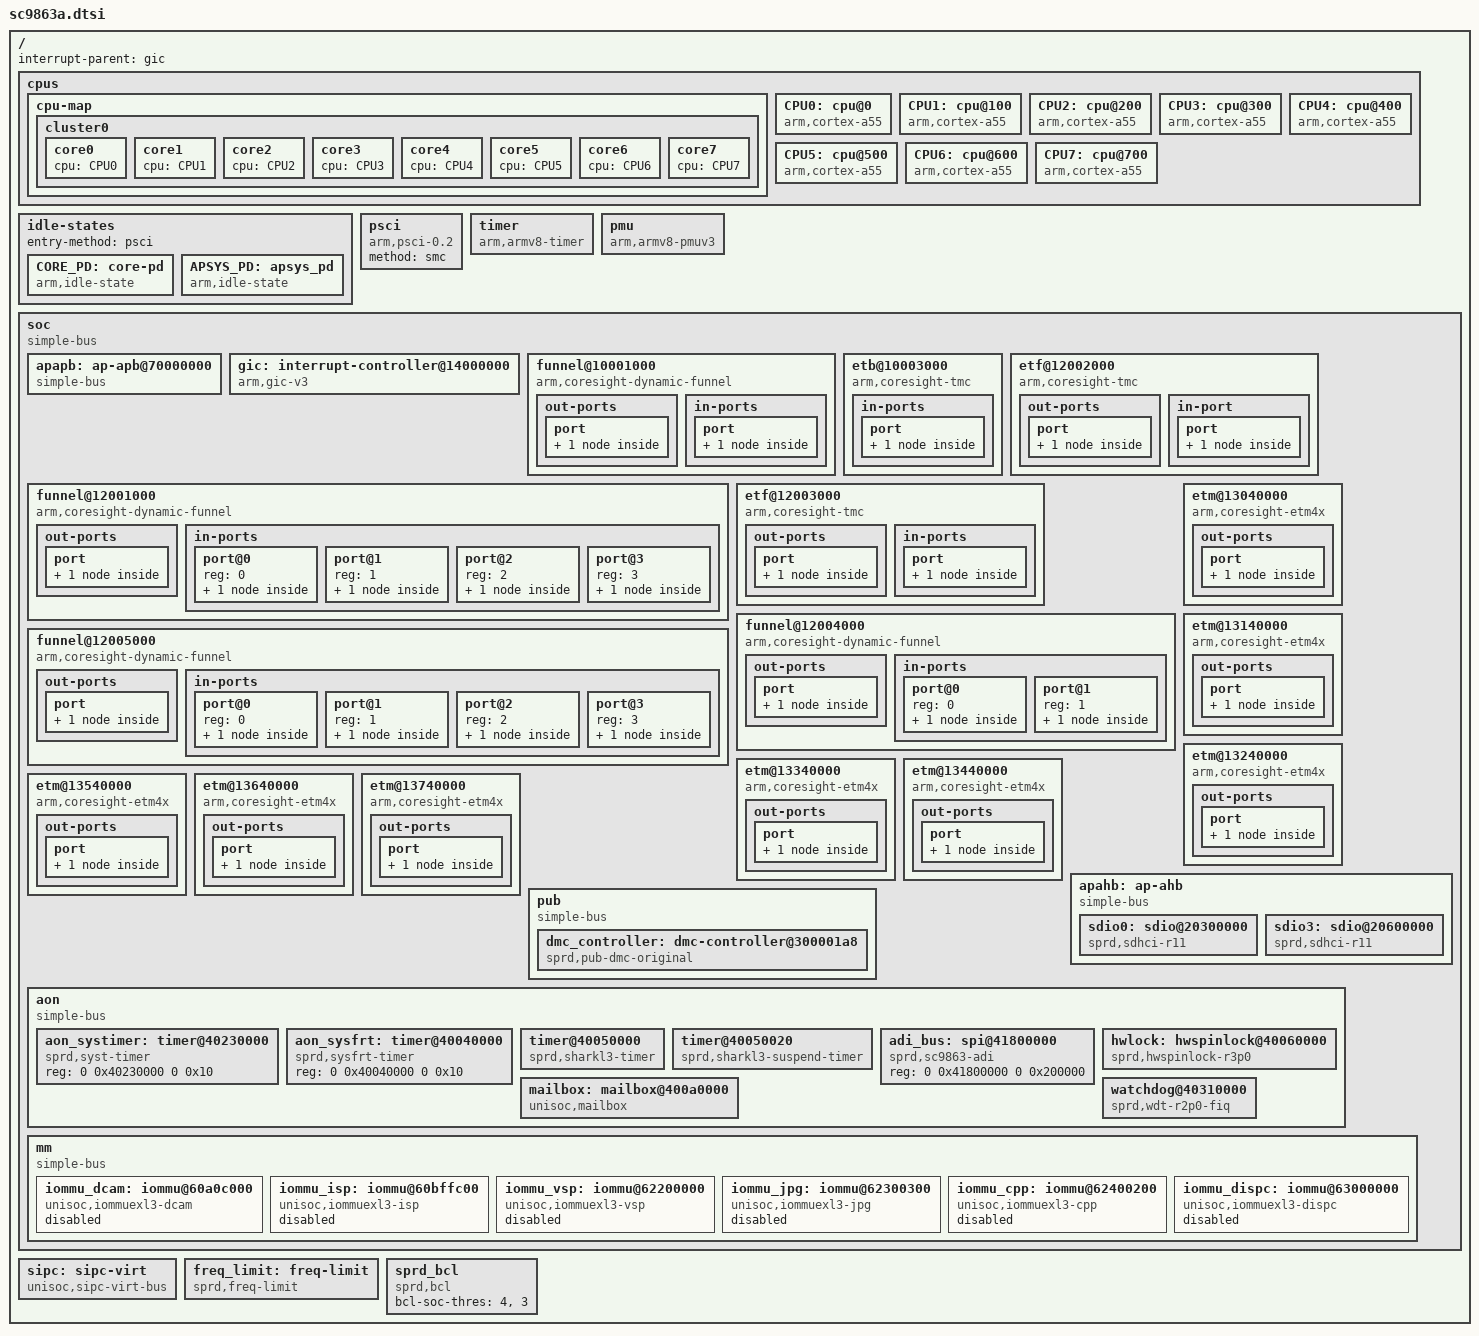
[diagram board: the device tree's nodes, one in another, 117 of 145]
// SPDX-License-Identifier: GPL-2.0-only
/*
 * Unisoc SC9863A SoC DTS file
 *
 * Copyright (C) 2019, Unisoc Inc.
 */

#include <dt-bindings/clock/sprd,sc9863a-clk.h>
#include <dt-bindings/reset/sprd,sc9863a-reset.h>
#include <dt-bindings/interrupt-controller/arm-gic.h>

/ {

	interrupt-parent = <&gic>;
	#address-cells = <2>;
	#size-cells = <2>;

	cpus {
		#address-cells = <2>;
		#size-cells = <0>;

		cpu-map {
			cluster0 {
				core0 {
					cpu = <&CPU0>;
				};
				core1 {
					cpu = <&CPU1>;
				};
				core2 {
					cpu = <&CPU2>;
				};
				core3 {
					cpu = <&CPU3>;
				};
				core4 {
					cpu = <&CPU4>;
				};
				core5 {
					cpu = <&CPU5>;
				};
				core6 {
					cpu = <&CPU6>;
				};
				core7 {
					cpu = <&CPU7>;
				};
			};
		};

		CPU0: cpu@0 {
			device_type = "cpu";
			compatible = "arm,cortex-a55";
			reg = <0x0 0x0>;
			enable-method = "psci";
			cpu-idle-states = <&CORE_PD &APSYS_PD>;
			capacity-dmips-mhz = <1024>;
			dynamic-power-coefficient = <100>;
			sugov_slack_timer;
			#cooling-cells = <2>;
		};

		CPU1: cpu@100 {
			device_type = "cpu";
			compatible = "arm,cortex-a55";
			reg = <0x0 0x100>;
			enable-method = "psci";
			cpu-idle-states = <&CORE_PD &APSYS_PD>;
			capacity-dmips-mhz = <1024>;
			dynamic-power-coefficient = <100>;
			#cooling-cells = <2>;
		};

		CPU2: cpu@200 {
			device_type = "cpu";
			compatible = "arm,cortex-a55";
			reg = <0x0 0x200>;
			enable-method = "psci";
			cpu-idle-states = <&CORE_PD &APSYS_PD>;
			capacity-dmips-mhz = <1024>;
			dynamic-power-coefficient = <100>;
			#cooling-cells = <2>;
		};

		CPU3: cpu@300 {
			device_type = "cpu";
			compatible = "arm,cortex-a55";
			reg = <0x0 0x300>;
			enable-method = "psci";
			cpu-idle-states = <&CORE_PD &APSYS_PD>;
			capacity-dmips-mhz = <1024>;
			dynamic-power-coefficient = <100>;
			#cooling-cells = <2>;
		};

		CPU4: cpu@400 {
			device_type = "cpu";
			compatible = "arm,cortex-a55";
			reg = <0x0 0x400>;
			enable-method = "psci";
			cpu-idle-states = <&CORE_PD &APSYS_PD>;
			capacity-dmips-mhz = <1024>;
			dynamic-power-coefficient = <153>;
			#cooling-cells = <2>;
		};

		CPU5: cpu@500 {
			device_type = "cpu";
			compatible = "arm,cortex-a55";
			reg = <0x0 0x500>;
			enable-method = "psci";
			cpu-idle-states = <&CORE_PD &APSYS_PD>;
			capacity-dmips-mhz = <1024>;
			dynamic-power-coefficient = <153>;
			#cooling-cells = <2>;
		};

		CPU6: cpu@600 {
			device_type = "cpu";
			compatible = "arm,cortex-a55";
			reg = <0x0 0x600>;
			enable-method = "psci";
			cpu-idle-states = <&CORE_PD &APSYS_PD>;
			capacity-dmips-mhz = <1024>;
			dynamic-power-coefficient = <153>;
			#cooling-cells = <2>;
		};

		CPU7: cpu@700 {
			device_type = "cpu";
			compatible = "arm,cortex-a55";
			reg = <0x0 0x700>;
			enable-method = "psci";
			cpu-idle-states = <&CORE_PD &APSYS_PD>;
			capacity-dmips-mhz = <1024>;
			dynamic-power-coefficient = <153>;
			#cooling-cells = <2>;
		};
	};

	idle-states {
		entry-method = "psci";
		CORE_PD: core-pd {
			compatible = "arm,idle-state";
			entry-latency-us = <4000>;
			exit-latency-us = <4000>;
			min-residency-us = <10000>;
			local-timer-stop;
			arm,psci-suspend-param = <0x00010000>;
		};
		APSYS_PD: apsys_pd {
			compatible = "arm,idle-state";
			entry-latency-us = <12000>;
			exit-latency-us = <12000>;
			min-residency-us = <15000>;
			local-timer-stop;
			arm,psci-suspend-param = <0x02010000>;
		};
	};

	psci {
		compatible = "arm,psci-0.2";
		method = "smc";
	};

	timer {
		compatible = "arm,armv8-timer";
		interrupts = <GIC_PPI 13 IRQ_TYPE_LEVEL_HIGH>, /* Physical Secure PPI */
			     <GIC_PPI 14 IRQ_TYPE_LEVEL_HIGH>, /* Physical Non-Secure PPI */
			     <GIC_PPI 11 IRQ_TYPE_LEVEL_HIGH>, /* Virtual PPI */
			     <GIC_PPI 10 IRQ_TYPE_LEVEL_HIGH>; /* Hipervisor PPI */
		arm,no-tick-in-suspend;
	};

	pmu {
		compatible = "arm,armv8-pmuv3";
		interrupts = <GIC_SPI 144 IRQ_TYPE_LEVEL_HIGH>,
			     <GIC_SPI 145 IRQ_TYPE_LEVEL_HIGH>,
			     <GIC_SPI 146 IRQ_TYPE_LEVEL_HIGH>,
			     <GIC_SPI 147 IRQ_TYPE_LEVEL_HIGH>,
			     <GIC_SPI 148 IRQ_TYPE_LEVEL_HIGH>,
			     <GIC_SPI 149 IRQ_TYPE_LEVEL_HIGH>,
			     <GIC_SPI 150 IRQ_TYPE_LEVEL_HIGH>,
			     <GIC_SPI 151 IRQ_TYPE_LEVEL_HIGH>;
	};

	soc: soc {

		compatible = "simple-bus";
		#address-cells = <2>;
		#size-cells = <2>;
		ranges;

		apapb: ap-apb@70000000 {
			compatible = "simple-bus";
			#address-cells = <1>;
			#size-cells = <1>;
			ranges = <0 0x0 0x70000000 0x10000000>;
		};

		gic: interrupt-controller@14000000 {
			compatible = "arm,gic-v3";
			#interrupt-cells = <3>;
			#address-cells = <2>;
			#size-cells = <2>;
			ranges;
			redistributor-stride = <0x0 0x20000>;	/* 128KB stride */
			#redistributor-regions = <1>;
			interrupt-controller;
			reg = <0x0 0x14000000 0 0x20000>,	/* GICD */
			      <0x0 0x14040000 0 0x100000>;	/* GICR */
			interrupts = <GIC_PPI 9 IRQ_TYPE_LEVEL_HIGH>;
		};

		funnel@10001000 {
			compatible = "arm,coresight-dynamic-funnel", "arm,primecell";
			reg = <0 0x10001000 0 0x1000>;
			clocks = <&ext_26m>;
			clock-names = "apb_pclk";

			out-ports {
				port {
					funnel_soc_out_port: endpoint {
						remote-endpoint = <&etb_in>;
					};
				};
			};

			in-ports {
				port {
					funnel_soc_in_port: endpoint {
						remote-endpoint =
						<&funnel_ca55_out_port>;
					};
				};
			};
		};

		etb@10003000 {
			compatible = "arm,coresight-tmc", "arm,primecell";
			reg = <0 0x10003000 0 0x1000>;
			clocks = <&ext_26m>;
			clock-names = "apb_pclk";

			in-ports {
				port {
					etb_in: endpoint {
						remote-endpoint =
						<&funnel_soc_out_port>;
					};
				};
			};
		};

		funnel@12001000 {
			compatible = "arm,coresight-dynamic-funnel", "arm,primecell";
			reg = <0 0x12001000 0 0x1000>;
			clocks = <&ext_26m>;
			clock-names = "apb_pclk";

			out-ports {
				port {
					funnel_little_out_port: endpoint {
						remote-endpoint =
						<&etf_little_in>;
					};
				};
			};

			in-ports {
				#address-cells = <1>;
				#size-cells = <0>;

				port@0 {
					reg = <0>;
					funnel_little_in_port0: endpoint {
						remote-endpoint = <&etm0_out>;
					};
				};

				port@1 {
					reg = <1>;
					funnel_little_in_port1: endpoint {
						remote-endpoint = <&etm1_out>;
					};
				};

				port@2 {
					reg = <2>;
					funnel_little_in_port2: endpoint {
						remote-endpoint = <&etm2_out>;
					};
				};

				port@3 {
					reg = <3>;
					funnel_little_in_port3: endpoint {
						remote-endpoint = <&etm3_out>;
					};
				};
			};
		};

		etf@12002000 {
			compatible = "arm,coresight-tmc", "arm,primecell";
			reg = <0 0x12002000 0 0x1000>;
			clocks = <&ext_26m>;
			clock-names = "apb_pclk";

			out-ports {
				port {
					etf_little_out: endpoint {
						remote-endpoint =
						<&funnel_ca55_in_port0>;
					};
				};
			};

			in-port {
				port {
					etf_little_in: endpoint {
						remote-endpoint =
						<&funnel_little_out_port>;
					};
				};
			};
		};

		etf@12003000 {
			compatible = "arm,coresight-tmc", "arm,primecell";
			reg = <0 0x12003000 0 0x1000>;
			clocks = <&ext_26m>;
			clock-names = "apb_pclk";

			out-ports {
				port {
					etf_big_out: endpoint {
						remote-endpoint =
						<&funnel_ca55_in_port1>;
					};
				};
			};

			in-ports {
				port {
					etf_big_in: endpoint {
						remote-endpoint =
						<&funnel_big_out_port>;
					};
				};
			};
		};

		funnel@12004000 {
			compatible = "arm,coresight-dynamic-funnel", "arm,primecell";
			reg = <0 0x12004000 0 0x1000>;
			clocks = <&ext_26m>;
			clock-names = "apb_pclk";

			out-ports {
				port {
					funnel_ca55_out_port: endpoint {
						remote-endpoint =
						<&funnel_soc_in_port>;
					};
				};
			};

			in-ports {
				#address-cells = <1>;
				#size-cells = <0>;

				port@0 {
					reg = <0>;
					funnel_ca55_in_port0: endpoint {
						remote-endpoint =
						<&etf_little_out>;
					};
				};

				port@1 {
					reg = <1>;
					funnel_ca55_in_port1: endpoint {
						remote-endpoint =
						<&etf_big_out>;
					};
				};
			};
		};

		funnel@12005000 {
			compatible = "arm,coresight-dynamic-funnel", "arm,primecell";
			reg = <0 0x12005000 0 0x1000>;
			clocks = <&ext_26m>;
			clock-names = "apb_pclk";

			out-ports {
				port {
					funnel_big_out_port: endpoint {
						remote-endpoint =
						<&etf_big_in>;
					};
				};
			};

			in-ports {
				#address-cells = <1>;
				#size-cells = <0>;

				port@0 {
					reg = <0>;
					funnel_big_in_port0: endpoint {
						remote-endpoint = <&etm4_out>;
					};
				};

				port@1 {
					reg = <1>;
					funnel_big_in_port1: endpoint {
						remote-endpoint = <&etm5_out>;
					};
				};

				port@2 {
					reg = <2>;
					funnel_big_in_port2: endpoint {
						remote-endpoint = <&etm6_out>;
					};
				};

				port@3 {
					reg = <3>;
					funnel_big_in_port3: endpoint {
						remote-endpoint = <&etm7_out>;
					};
				};
			};
		};

		etm@13040000 {
			compatible = "arm,coresight-etm4x", "arm,primecell";
			reg = <0 0x13040000 0 0x1000>;
			cpu = <&CPU0>;
			clocks = <&ext_26m>;
			clock-names = "apb_pclk";

			out-ports {
				port {
					etm0_out: endpoint {
						remote-endpoint =
						<&funnel_little_in_port0>;
					};
				};
			};
		};

		etm@13140000 {
			compatible = "arm,coresight-etm4x", "arm,primecell";
			reg = <0 0x13140000 0 0x1000>;
			cpu = <&CPU1>;
			clocks = <&ext_26m>;
			clock-names = "apb_pclk";

			out-ports {
				port {
					etm1_out: endpoint {
						remote-endpoint =
						<&funnel_little_in_port1>;
					};
				};
			};
		};

		etm@13240000 {
			compatible = "arm,coresight-etm4x", "arm,primecell";
			reg = <0 0x13240000 0 0x1000>;
			cpu = <&CPU2>;
			clocks = <&ext_26m>;
			clock-names = "apb_pclk";

			out-ports {
				port {
					etm2_out: endpoint {
						remote-endpoint =
						<&funnel_little_in_port2>;
					};
				};
			};
		};

		etm@13340000 {
			compatible = "arm,coresight-etm4x", "arm,primecell";
			reg = <0 0x13340000 0 0x1000>;
			cpu = <&CPU3>;
			clocks = <&ext_26m>;
			clock-names = "apb_pclk";

			out-ports {
				port {
					etm3_out: endpoint {
						remote-endpoint =
						<&funnel_little_in_port3>;
					};
				};
			};
		};

		etm@13440000 {
			compatible = "arm,coresight-etm4x", "arm,primecell";
			reg = <0 0x13440000 0 0x1000>;
			cpu = <&CPU4>;
			clocks = <&ext_26m>;
			clock-names = "apb_pclk";

			out-ports {
				port {
					etm4_out: endpoint {
						remote-endpoint =
						<&funnel_big_in_port0>;
					};
				};
			};
		};

		etm@13540000 {
			compatible = "arm,coresight-etm4x", "arm,primecell";
			reg = <0 0x13540000 0 0x1000>;
			cpu = <&CPU5>;
			clocks = <&ext_26m>;
			clock-names = "apb_pclk";

			out-ports {
				port {
					etm5_out: endpoint {
						remote-endpoint =
						<&funnel_big_in_port1>;
					};
				};
			};
		};

		etm@13640000 {
			compatible = "arm,coresight-etm4x", "arm,primecell";
			reg = <0 0x13640000 0 0x1000>;
			cpu = <&CPU6>;
			clocks = <&ext_26m>;
			clock-names = "apb_pclk";

			out-ports {
				port {
					etm6_out: endpoint {
						remote-endpoint =
						<&funnel_big_in_port2>;
					};
				};
			};
		};

		etm@13740000 {
			compatible = "arm,coresight-etm4x", "arm,primecell";
			reg = <0 0x13740000 0 0x1000>;
			cpu = <&CPU7>;
			clocks = <&ext_26m>;
			clock-names = "apb_pclk";

			out-ports {
				port {
					etm7_out: endpoint {
						remote-endpoint =
						<&funnel_big_in_port3>;
					};
				};
			};
		};

		apahb: ap-ahb {
			compatible = "simple-bus";
			#address-cells = <2>;
			#size-cells = <2>;
			ranges;

			sdio0: sdio@20300000 {
				compatible  = "sprd,sdhci-r11";
				reg = <0 0x20300000 0 0x1000>;
				interrupts = <GIC_SPI 57 IRQ_TYPE_LEVEL_HIGH>;

				clock-names = "sdio", "enable";
				clocks = <&aon_clk CLK_SDIO0_2X>,
					 <&apahb_gate CLK_SDIO0_EB>;
				assigned-clocks = <&aon_clk CLK_SDIO0_2X>;
				assigned-clock-parents = <&rpll CLK_RPLL_390M>;
			};

			sdio3: sdio@20600000 {
				compatible  = "sprd,sdhci-r11";
				reg = <0 0x20600000 0 0x1000>;
				interrupts = <GIC_SPI 60 IRQ_TYPE_LEVEL_HIGH>;

				clock-names = "sdio", "enable";
				clocks = <&aon_clk CLK_EMMC_2X>,
					 <&apahb_gate CLK_EMMC_EB>;
				assigned-clocks = <&aon_clk CLK_EMMC_2X>;
				assigned-clock-parents = <&rpll CLK_RPLL_390M>;
			};
		};

		pub: pub {
			compatible = "simple-bus";
			#address-cells = <2>;
			#size-cells = <2>;
			ranges;

			dmc_controller: dmc-controller@300001a8 {
				compatible = "sprd,pub-dmc-original";
				reg = <0x0 0x300001a8 0x0 0x100>,
					<0x0 0x30000000 0x0 0x12c>;
			};
		};

		aon: aon {
			compatible = "simple-bus";
			#address-cells = <2>;
			#size-cells = <2>;
			ranges;

			aon_systimer: timer@40230000 {
				compatible = "sprd,syst-timer";
				reg = <0 0x40230000 0 0x10>;
			};

			aon_sysfrt: timer@40040000 {
				compatible = "sprd,sysfrt-timer";
				reg = <0 0x40040000 0 0x10>;
			};

			timer@40050000 {
				compatible = "sprd,sharkl3-timer",
						"sprd,sc9860-timer";
				reg = <0 0x40050000 0 0x14>;
				interrupts = <GIC_SPI 27 IRQ_TYPE_LEVEL_HIGH>;
				clocks = <&ext_32k>;
			};

			timer@40050020 {
				compatible = "sprd,sharkl3-suspend-timer",
					"sprd,sc9860-suspend-timer";
				reg = <0 0x40050020 0 0x14>;
				clocks = <&ext_32k>;
			};

			adi_bus: spi@41800000 {
				compatible = "sprd,sc9863-adi";
				reg = <0 0x41800000 0 0x200000>;
				#address-cells = <1>;
				#size-cells = <0>;
			};

			hwlock: hwspinlock@40060000 {
				compatible = "sprd,hwspinlock-r3p0";
				reg = <0 0x40060000 0 0x10000>;
				#hwlock-cells = <1>;
				clock-names = "enable";
				clocks = <&aonapb_gate CLK_SPLK_EB>;
			};

			mailbox: mailbox@400a0000 {
				compatible = "unisoc,mailbox";
				reg = <0 0x400a0000 0 0x8000>,
				      <0 0x400a8000 0 0x8000>;
				reg-names = "inbox", "outbox";
				sprd,mailbox_clk = <&aon_apb_regs 0x4 0x200000>;
				interrupts = <GIC_SPI 68 IRQ_TYPE_LEVEL_HIGH>,
					     <GIC_SPI 69 IRQ_TYPE_LEVEL_HIGH>,
					     <GIC_SPI 119 IRQ_TYPE_LEVEL_HIGH>;
				interrupt-names = "inbox", "outbox", "oob-outbox";
				#mbox-cells = <2>;
			};
			watchdog@40310000 {
				compatible = "sprd,wdt-r2p0-fiq";
				reg = <0 0x40310000 0 0x1000>;
				interrupts = <GIC_SPI 124 IRQ_TYPE_LEVEL_HIGH>;
				timeout-sec = <30>;
				clock-names = "enable", "rtc_enable";
				clocks = <&aonapb_gate CLK_CA53_WDG_EB>,
					<&aonapb_gate CLK_CA53_WDG_RTC_EB>;
			};
		};

		mm: mm {
			compatible = "simple-bus";
			#address-cells = <2>;
			#size-cells = <2>;
			ranges;

			iommu_dcam: iommu@60a0c000 {
				compatible = "unisoc,iommuexl3-dcam";
				reg = <0 0x60a00000 0 0xc000>,
					<0 0x60a0c000 0 0x60>;
				iova-base = <0x40000000>;
				iova-size = <0x20000000>;
				reg_name = "mmu_interrupt_reg", "mmu_reg";
				status = "disabled";
				#iommu-cells = <0>;
			};
			iommu_isp: iommu@60bffc00 {
				compatible = "unisoc,iommuexl3-isp";
				/* sharkl3 isp need pagetalbe size */
				reg = <0 0x60b00000 0 0xffc00>,
					<0 0x60bffc00 0 0x400>;
				iova-base = <0x50000000>;
				iova-size = <0x20000000>;
				reg_name = "mmu_interrupt_reg","mmu_reg";
				status = "disabled";
				#iommu-cells = <0>;
			};

			iommu_vsp: iommu@62200000 {
				compatible = "unisoc,iommuexl3-vsp";
				reg = <0x0 0x62200000 0x0 0x80>,
					<0x0 0x62200000 0x0 0x80>;
				iova-base = <0x20000000>;
				iova-size = <0x10000000>;
				reg_name = "mmu_interrupt_reg","mmu_reg";
				status = "disabled";
				#iommu-cells = <0>;
			};

			iommu_jpg: iommu@62300300 {
				compatible = "unisoc,iommuexl3-jpg";
				reg = <0x0 0x62300000 0x0 0x300>,
					<0x0 0x62300300 0x0 0x80>;
				iova-base = <0x70000000>;
				iova-size = <0x10000000>;
				reg_name = "mmu_interrupt_reg","mmu_reg";
				status = "disabled";
				#iommu-cells = <0>;
			};

			iommu_cpp: iommu@62400200 {
				compatible = "unisoc,iommuexl3-cpp";
				reg = <0 0x62400000 0 0x200>,
					<0 0x62400200 0 0x60>;
				iova-base = <0x60000000>;
				iova-size = <0x8000000>;
				reg_name = "mmu_interrupt_reg","mmu_reg";
				status = "disabled";
				#iommu-cells = <0>;
			};

			iommu_dispc: iommu@63000000 {
				compatible = "unisoc,iommuexl3-dispc";
				reg = <0x0 0x63000000 0x0 0x800>,
					<0x0 0x63000800 0x0 0x80>;
				iova-base = <0x30000000>;
				iova-size = <0x10000000>;
				reg_name = "mmu_interrupt_reg","mmu_reg";
				status = "disabled";
				#iommu-cells = <0>;
			};
		};
	};

	sipc: sipc-virt {
		compatible = "unisoc,sipc-virt-bus";
		#address-cells = <1>;
		#size-cells = <0>;
	};

	freq_limit: freq-limit {
		compatible = "sprd,freq-limit";
		sprd,device-sign = <0x3>;
		sprd,devfreq-cells = <&gpu>;
	};

	sprd_bcl: sprd_bcl {
		compatible = "sprd,bcl";
		bcl-soc-thres = <4>, <3>;
	};
};

&sdio0 {
	sprd,phy-delay-sd-uhs-sdr104 = <0x7f 0xd1 0xd1 0xd1>;
	sprd,phy-delay-sd-uhs-sdr50 = <0x7f 0xff 0xff 0xff>;
	sprd,phy-delay-sd-highspeed = <0x7f 0x23 0x22 0x22>;
	vmmc-supply = <&vddsdcore>;
	vqmmc-supply = <&vddsdio>;
	voltage-ranges = <3000 3000>;
	bus-width = <4>;
	sd-uhs-sdr104;
	sd-uhs-sdr50;
	sprd,name = "sdio_sd";
	no-sdio;
	no-mmc;
	status = "okay";
};

&sdio3 {
	sprd,phy-delay-mmc-hs400es = <0x55 0x7f 0x38 0x38>;
	sprd,phy-delay-mmc-hs400 = <0x55 0xd3 0x35 0x35>;
	sprd,phy-delay-mmc-hs200 = <0x7f 0xcd 0xcd 0xcd>;
	sprd,phy-delay-mmc-ddr52 = <0x32 0x23 0x18 0x18>;
	sprd,phy-delay-mmc-highspeed = <0x00 0x38 0x00 0x00>;
	vmmc-supply = <&vddemmccore>;
	voltage-ranges = <3000 3000>;
	bus-width = <8>;
	non-removable;
	cap-mmc-hw-reset;
	mmc-hs400-enhanced-strobe;
	mmc-hs400-1_8v;
	mmc-hs200-1_8v;
	mmc-ddr-1_8v;
	sprd,name = "sdio_emmc";
	no-sdio;
	no-sd;
	status = "okay";
	supports-swcq;
};


/* Include other IP modules in ALPHABETICAL order */
#include "bm.dtsi"
#include "ddr-dfs.dtsi"
#include "dma.dtsi"
#include "dmc-mpu.dtsi"
#include "glbreg.dtsi"
#include "cam.dtsi"
#include "csi.dtsi"
#include "gpio.dtsi"
#include "i2c.dtsi"
#include "i2s.dtsi"
#include "modem.dtsi"
#include "power.dtsi"
#include "pnp.dtsi"
#include "ptm.dtsi"
#include "pwm.dtsi"
#include "pin-controller.dtsi"
#include "audio.dtsi"
#include "sensorhub.dtsi"
#include "spi.dtsi"
#include "uart.dtsi"
#include "efuse.dtsi"
#include "gpu.dtsi"
#include "usb.dtsi"
#include "dispc.dtsi"
#include "vsp.dtsi"
#include "jpg.dtsi"
#include "apcpu-dvfs.dtsi"
#include "thermal.dtsi"
#include "mipi-serdes.dtsi"
